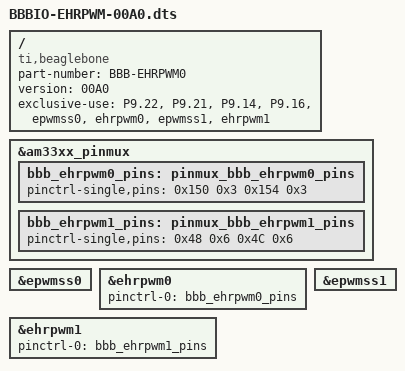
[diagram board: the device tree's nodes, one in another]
/*
 * Copyright (C) 2014
 *
 * Virtual cape for ehrPWM0, ehrPWM1, ehrPWM2 on connector pins P9.29 P9.31.
 *
 * This program is free software; you can redistribute it and/or modify
 * it under the terms of the GNU General Public License version 2 as
 * published by the Free Software Foundation.
 *
 */

/dts-v1/;
/plugin/;
 
/ {
   	compatible = "ti,beaglebone", "ti,beaglebone-black";
 
        /* identification */
	part-number = "BBB-EHRPWM0";
	version = "00A0";


	/* state the resources this cape uses */
	exclusive-use =
		/* the pin header uses */
		"P9.22",        /* ehrpwm0A */
		"P9.21",        /* ehrpwm0B */
		"P9.14",	/* ehrpwm1A */
		"P9.16",	/* ehrpwm1B */
                /* the hardware ip uses */
		"epwmss0",
		"ehrpwm0",
		"epwmss1",
		"ehrpwm1";
 
        fragment@0 {
                target = <&am33xx_pinmux>;
                __overlay__ {
                        bbb_ehrpwm0_pins: pinmux_bbb_ehrpwm0_pins {
                                pinctrl-single,pins = <
					0x150 0x3	/* spi0_sclk.ehrpwm0A , OUTPUT_PULLDOWN | MODE3 P9_22*/
					0x154 0x3	/* spi0_d0  .ehrpwm0B , OUTPUT_PULLDOWN | MODE3 P9_21*/
                                >;	
                        };
                        bbb_ehrpwm1_pins: pinmux_bbb_ehrpwm1_pins {
                                pinctrl-single,pins = <
					0x48 0x6       /* gpmc_a2.ehrpwm1A , OUTPUT_PULLDOWN | MODE3 P9_14*/
					0x4C 0x6       /* gpmc_a3.ehrpwm1B , OUTPUT_PULLDOWN | MODE3 P9_16*/
                                >;	
                        };
               };
        };
 
	fragment@1 {
                target = <&epwmss0>;
                __overlay__ {
                        status = "okay";
                        pinctrl-names = "default";
                };
        };
	fragment@2 {
                target = <&ehrpwm0>;
                __overlay__ {
                        status = "okay";
                        pinctrl-names = "default";
                        pinctrl-0 = <&bbb_ehrpwm0_pins>;
                };
        };
	
	fragment@3 {
                target = <&epwmss1>;
                __overlay__ {
                        status = "okay";
                        pinctrl-names = "default";
                };
        };
	fragment@4 {
                target = <&ehrpwm1>;
                __overlay__ {
                        status = "okay";
                        pinctrl-names = "default";
                        pinctrl-0 = <&bbb_ehrpwm1_pins>;
                };
        };
};
